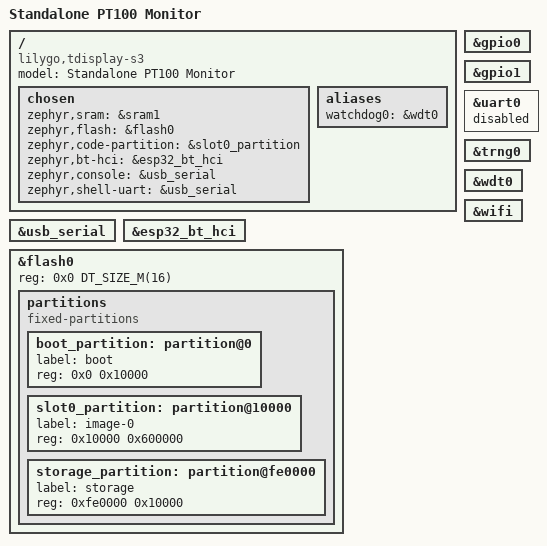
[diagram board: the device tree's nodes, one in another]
/dts-v1/;
#include <espressif/esp32s3/esp32s3_wroom_n8.dtsi>
#include <zephyr/dt-bindings/gpio/gpio.h>

/ {
    model = "Standalone PT100 Monitor";
    compatible = "lilygo,tdisplay-s3";
    chosen {
        zephyr,sram = &sram1;
        zephyr,flash = &flash0;
        zephyr,code-partition = &slot0_partition;
        zephyr,bt-hci = &esp32_bt_hci;
        zephyr,console = &usb_serial;
        zephyr,shell-uart = &usb_serial;

    };
    aliases { watchdog0 = &wdt0; };

};
&gpio0 { status = "okay"; };
&gpio1 { status = "okay"; };
&usb_serial { status = "okay"; };
&uart0 { status = "disabled"; };
&esp32_bt_hci { status = "okay"; };
&trng0 { status = "okay"; };
&wdt0 { status = "okay"; };
&flash0 {
    reg = <0x0 DT_SIZE_M(16)>;
    partitions {
        compatible = "fixed-partitions";
        #address-cells = <1>; #size-cells = <1>;
        boot_partition: partition@0 { label = "boot"; reg = <0x0 0x10000>; };
        slot0_partition: partition@10000 { label = "image-0"; reg = <0x10000 0x600000>; };
        storage_partition: partition@fe0000 { label = "storage"; reg = <0xfe0000 0x10000>; };
    };
};

&wifi { status = "okay"; };
